# earlgrey register map
Vendor: lowRISC; File version: 0.1
CPU: ibex rev01, little endian, no MPU, no FPU, VTOR, 2 interrupt priority bits, 2 interrupts
Registers are 32-bit, read-write, no defined reset value unless marked. A register's access mark holds for its fields unless they carry their own. Offsets are from the block's base; [hi:lo] are bit positions.

## OTBN — Programmable coprocessor for asymmetric cryptography with SCA and FI countermeasures
Base 0x41130000
0x40 CMD wo — Command RegisterA command initiates an OTBN operation. While performing the operation,OTBN is busy; the !!STATUS register reflects that.All operations signal their completion by raising the doneinterrupt; alternatively, software may poll the !!STATUS register.Writes are ignored if OTBN is not idle.Unrecognized commands are ignored.
  [7:0] cmd — The operation to perform.| Value | Name | Description ||:------|:--------------|:------------|| 0xd8 | EXECUTE | Starts the execution of the program stored in the instruction memory, starting at address zero. || 0xc3 | SEC_WIPE_DMEM | Securely removes all contents from the data memory. || 0x1e | SEC_WIPE_IMEM | Securely removes all contents from the instruction memory. |
0x44 CTRL — Control Register
  [0] software_errs_fatal — Controls the reaction to software errors.When set software errors produce fatal errors, rather thanrecoverable errors.Writes are ignored if OTBN is not idle.
0x48 STATUS ro
  [7:0] status — Indicates the current operational state OTBN is in.All BUSY values represent an operation started by a write to the!!CMD register.| Value | Name | Description ||:------|:-------------------|:------------------------------------------------------|| 0x00 | IDLE | OTBN is idle: it is not performing any action. || 0x01 | BUSY_EXECUTE | OTBN is busy executing software. || 0x02 | BUSY_SEC_WIPE_DMEM | OTBN is busy securely wiping the data memory. || 0x03 | BUSY_SEC_WIPE_IMEM | OTBN is busy securely wiping the instruction memory. || 0x04 | BUSY_SEC_WIPE_INT | OTBN is busy securely wiping the internal state. || 0xFF | LOCKED | OTBN is locked as reaction to a fatal error, and must be reset to unlock it again. See also the section "Reaction to Fatal Errors". |
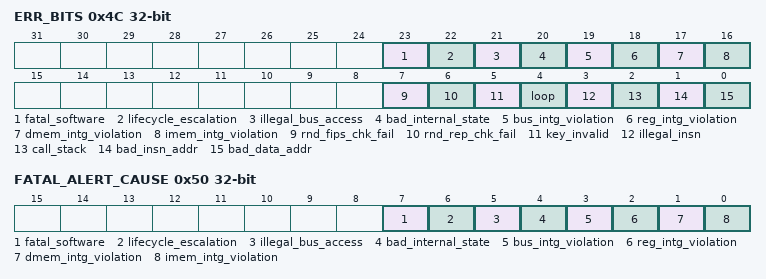
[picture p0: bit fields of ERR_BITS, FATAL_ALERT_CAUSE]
0x4C ERR_BITS — Operation Result RegisterDescribes the errors detected during an operation.Refer to the "List of Errors" section for a detailed description of theerrors.The host CPU can clear this register when OTBN is not running,by writing any value. Write attempts while OTBN is running are ignored.
  [23] fatal_software — A `FATAL_SOFTWARE` error was observed.
  [22] lifecycle_escalation — A `LIFECYCLE_ESCALATION` error was observed.
  [21] illegal_bus_access — An `ILLEGAL_BUS_ACCESS` error was observed.
  [20] bad_internal_state — A `BAD_INTERNAL_STATE` error was observed.
  [19] bus_intg_violation — A `BUS_INTG_VIOLATION` error was observed.
  [18] reg_intg_violation — A `REG_INTG_VIOLATION` error was observed.
  [17] dmem_intg_violation — A `DMEM_INTG_VIOLATION` error was observed.
  [16] imem_intg_violation — A `IMEM_INTG_VIOLATION` error was observed.
  [7] rnd_fips_chk_fail — An `RND_FIPS_CHK_FAIL` error was observed.
  [6] rnd_rep_chk_fail — An `RND_REP_CHK_FAIL` error was observed.
  [5] key_invalid — A `KEY_INVALID` error was observed.
  [4] loop — A `LOOP` error was observed.
  [3] illegal_insn — An `ILLEGAL_INSN` error was observed.
  [2] call_stack — A `CALL_STACK` error was observed.
  [1] bad_insn_addr — A `BAD_INSN_ADDR` error was observed.
  [0] bad_data_addr — A `BAD_DATA_ADDR` error was observed.
0x50 FATAL_ALERT_CAUSE ro — Fatal Alert Cause RegisterDescribes any errors that led to a fatal alert.A fatal error puts OTBN in locked state; the value of this registerdoes not change until OTBN is reset.Refer to the "List of Errors" section for a detailed description of theerrors.
  [7] fatal_software — A `FATAL_SOFTWARE` error was observed.
  [6] lifecycle_escalation — A `LIFECYCLE_ESCALATION` error was observed.
  [5] illegal_bus_access — A `ILLEGAL_BUS_ACCESS` error was observed.
  [4] bad_internal_state — A `BAD_INTERNAL_STATE` error was observed.
  [3] bus_intg_violation — A `BUS_INTG_VIOLATION` error was observed.
  [2] reg_intg_violation — A `REG_INTG_VIOLATION` error was observed.
  [1] dmem_intg_violation — A `DMEM_INTG_VIOLATION` error was observed.
  [0] imem_intg_violation — A `IMEM_INTG_VIOLATION` error was observed.
0x54 INSN_CNT — Instruction Count RegisterReturns the number of instructions executed in the current or lastoperation. The counter saturates at 2^32-1 and is reset to 0 at thestart of a new operation.Only the EXECUTE operation counts instructions; for all other operationsthis register remains at 0. Instructions triggering an error do notcount towards the total.Always reads as 0 if OTBN is locked.The host CPU can clear this register when OTBN is not running,by writing any value. Write attempts while OTBN is running are ignored.
  [31:0] insn_cnt — The number of executed instructions.
0x58 LOAD_CHECKSUM — A 32-bit CRC checksum of data written to memorySee the "Memory Load Integrity" section of the manual for full details.
  [31:0] checksum — Checksum accumulator
